# f28p65x_xbar_regs register map
Vendor: Texas Instruments
Peripheral module from a debugger description file (folder C2000).
Address unit: 16 bits
Registers are 32-bit, read-only, no defined reset value unless marked. A register's access mark holds for its fields unless they carry their own. Offsets are as the file gives them; lines under a group give offsets from that group; [hi:lo] are bit positions; {n}, {i} and the like mark numbered series; 'fields as' and 'values as' point back to an identical list; <NAME> marks a mode.

## XBAR_REGS — XBAR Registers
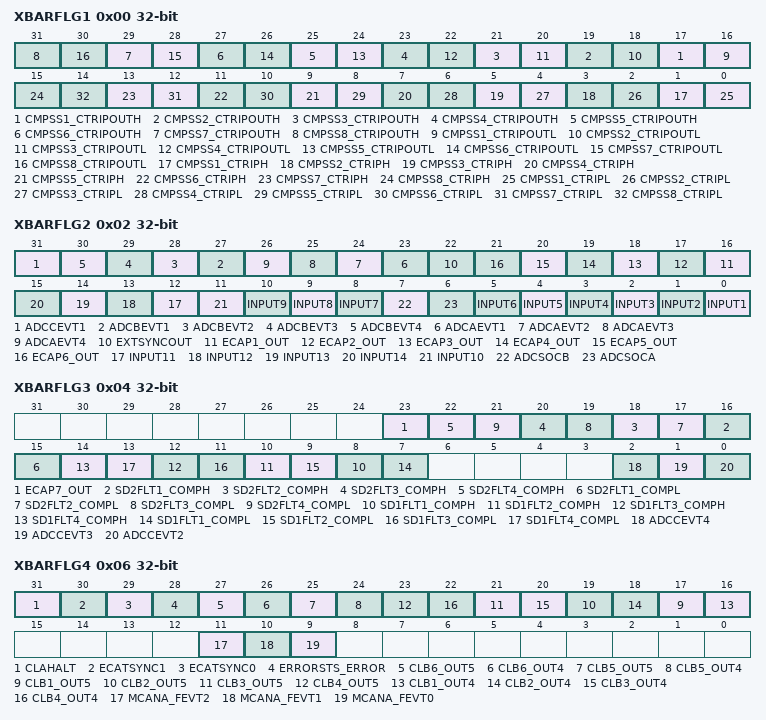
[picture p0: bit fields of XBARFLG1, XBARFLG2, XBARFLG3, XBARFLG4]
0x00 XBARFLG1 — X-Bar Input Flag Register 1
  [2n+15] CMPSS{n}_CTRIPOUTH (n=1..8) — Input Flag for CMPSS{n}.CTRIPOUTH Signal
  [2n+14] CMPSS{n}_CTRIPOUTL (n=1..8) — Input Flag for CMPSS{n}.CTRIPOUTL Signal
  [2n-1] CMPSS{n}_CTRIPH (n=1..8) — Input Flag for CMPSS{n}.CTRIPH Signal
  [2n-2] CMPSS{n}_CTRIPL (n=1..8) — Input Flag for CMPSS{n}.CTRIPL Signal
0x02 XBARFLG2 — X-Bar Input Flag Register 2
  [31] ADCCEVT1 — Input Flag for ADCCEVT1 Signal
  [n+26] ADCBEVT{n} (n=1..4) — Input Flag for ADCBEVT{n} Signal
  [n+22] ADCAEVT{n} (n=1..4) — Input Flag for ADCAEVT{n} Signal
  [22] EXTSYNCOUT — Input Flag for EXTSYNCOUT Signal
  [n+15] ECAP{n}_OUT (n=1..6) — Input Flag for ECAP{n}.OUT Signal
  [n+1] INPUT{n} (n=11..14) — Input Flag for INPUT{n} Signal
  [11] INPUT10 — Input Flag for INPUT10\ Signal
  [10] INPUT9 — Input Flag for INPUT9 Signal
  [9] INPUT8 — Input Flag for INPUT8 Signal
  [8] INPUT7 — Input Flag for INPUT7 Signal
  [7] ADCSOCB — Input Flag for ADCSOCB Signal
  [6] ADCSOCA — Input Flag for ADCSOCA Signal
  [n-1] INPUT{n} (n=1..6) — Input Flag for INPUT{n} Signal
0x04 XBARFLG3 — X-Bar Input Flag Register 3
  [23] ECAP7_OUT — Input Flag for ECAP7.OUT Signal
  [2n+14] SD2FLT{n}_COMPH (n=1..4) — Input Flag for SD2FLT{n}.COMPH Signal
  [2n+13] SD2FLT{n}_COMPL (n=1..4) — Input Flag for SD2FLT{n}.COMPL Signal
  [2n+6] SD1FLT{n}_COMPH (n=1..4) — Input Flag for SD1FLT{n}.COMPH Signal
  [2n+5] SD1FLT{n}_COMPL (n=1..4) — Input Flag for SD1FLT{n}.COMPL Signal
  [2] ADCCEVT4 — Input Flag for ADCCEVT4 Signal
  [1] ADCCEVT3 — Input Flag for ADCCEVT3 Signal
  [0] ADCCEVT2 — Input Flag for ADCCEVT2 Signal
0x06 XBARFLG4 — X-Bar Input Flag Register 4
  [31] CLAHALT — Input Latch for CLAHALT Signal
  [30] ECATSYNC1 — Input Latch for ECATSYNC1 Signal
  [29] ECATSYNC0 — Input Latch for ECATSYNC0 Signal
  [28] ERRORSTS_ERROR — Input Latch for ERRORSTS_ERROR Signal
  [27] CLB6_OUT5 — Input Latch for CLB6_OUT5 Signal
  [26] CLB6_OUT4 — Input Latch for CLB6_OUT4 Signal
  [25] CLB5_OUT5 — Input Latch for CLB5_OUT5 Signal
  [24] CLB5_OUT4 — Input Latch for CLB5_OUT4 Signal
  [2n+15] CLB{n}_OUT5 (n=1..4) — Input Flag for CLB{n}_5.1 Signal
  [2n+14] CLB{n}_OUT4 (n=1..4) — Input Flag for CLB{n}_4.1 Signal
  [11] MCANA_FEVT2 — Input Flag for MCANA_FEVT2 Signal
  [10] MCANA_FEVT1 — Input Flag for MCANA_FEVT1 Signal
  [9] MCANA_FEVT0 — Input Flag for MCANA_FEVT0 Signal
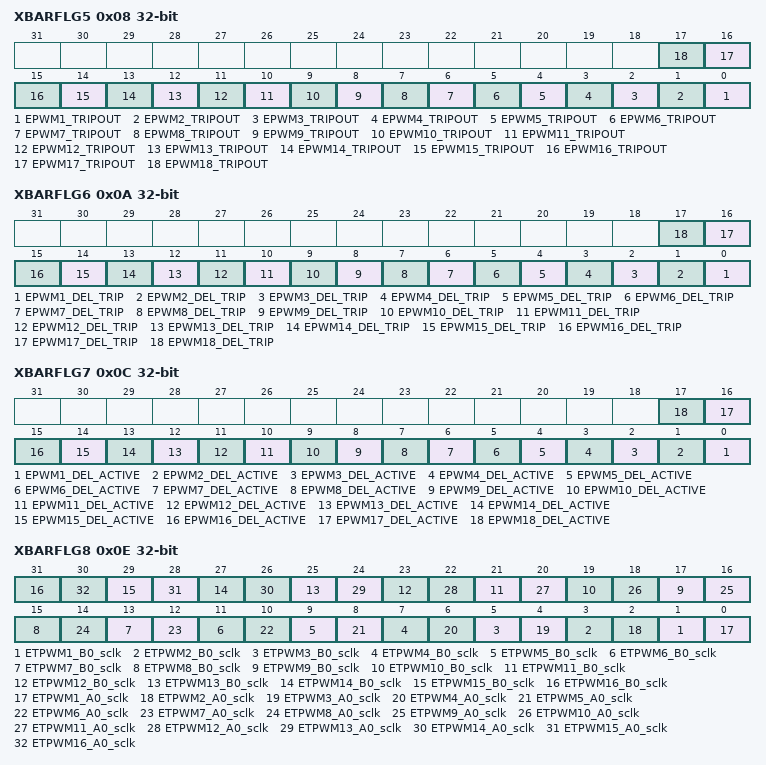
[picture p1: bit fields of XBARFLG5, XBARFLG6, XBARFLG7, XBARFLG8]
0x08 XBARFLG5 — X-Bar Input Flag Register 5
  [n-1] EPWM{n}_TRIPOUT (n=1..18) — Input Flag for EPWM{n}_TRIPOUT Signal
0x0A XBARFLG6 — X-Bar Input Flag Register 6
  [n-1] EPWM{n}_DEL_TRIP (n=1..18) — Input Flag for EPWM{n}_DEL_TRIP Signal
0x0C XBARFLG7 — X-Bar Input Flag Register 7
  [n-1] EPWM{n}_DEL_ACTIVE (n=1..18) — Input Flag for EPWM{n}_DEL_ACTIVE Signal
0x0E XBARFLG8 — X-Bar Input Flag Register 8
  [2n-1] ETPWM{n}_B0_sclk (n=1..16) — Input Flag for ETPWM{n}_B0_sclk Signal
  [2n-2] ETPWM{n}_A0_sclk (n=1..16) — Input Flag for ETPWM{n}_A0_sclk Signal
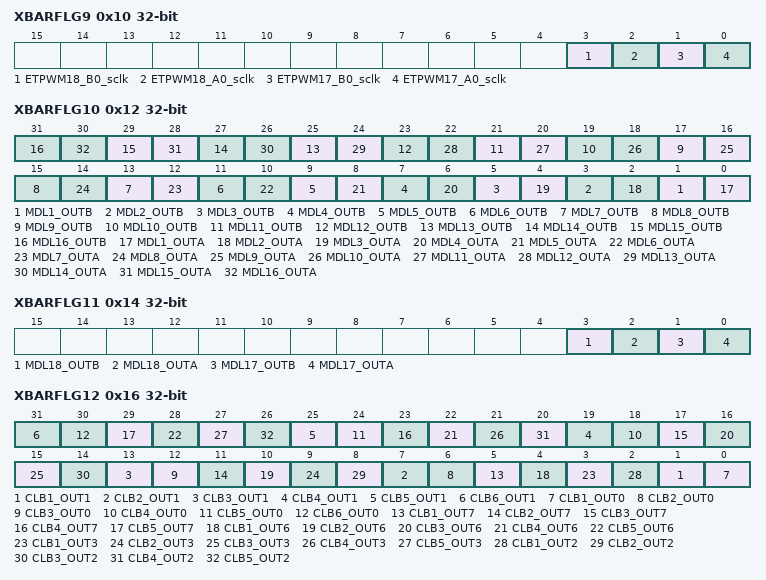
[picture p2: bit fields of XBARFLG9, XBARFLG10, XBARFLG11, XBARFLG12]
0x10 XBARFLG9 — X-Bar Input Flag Register 9
  [3] ETPWM18_B0_sclk — Input Flag for ETPWM18_B0_sclk Signal
  [2] ETPWM18_A0_sclk — Input Flag for ETPWM18_A0_sclk Signal
  [1] ETPWM17_B0_sclk — Input Flag for ETPWM17_B0_sclk Signal
  [0] ETPWM17_A0_sclk — Input Flag for ETPWM17_A0_sclk Signal
0x12 XBARFLG10 — X-Bar Input Flag Register 10
  [2n-1] MDL{n}_OUTB (n=1..16) — Input Flag for MDL{n}_OUTB Signal
  [2n-2] MDL{n}_OUTA (n=1..16) — Input Flag for MDL{n}_OUTA Signal
0x14 XBARFLG11 — X-Bar Input Flag Register 11
  [3] MDL18_OUTB — Input Flag for MDL18_OUTB Signal
  [2] MDL18_OUTA — Input Flag for MDL18_OUTA Signal
  [1] MDL17_OUTB — Input Flag for MDL17_OUTB Signal
  [0] MDL17_OUTA — Input Flag for MDL17_OUTA Signal
0x16 XBARFLG12 — X-Bar Input Flag Register 12
  [6n-5] CLB{n}_OUT1 (n=1..6) — Input Flag for CLB{n}_OUT1 Signal
  [6n-6] CLB{n}_OUT0 (n=1..6) — Input Flag for CLB{n}_OUT0 Signal
  [6n-1] CLB{n}_OUT7 (n=1..5) — Input Flag for CLB{n}_OUT7 Signal
  [6n-2] CLB{n}_OUT6 (n=1..5) — Input Flag for CLB{n}_OUT6 Signal
  [6n-3] CLB{n}_OUT3 (n=1..5) — Input Flag for CLB{n}_OUT3 Signal
  [6n-4] CLB{n}_OUT2 (n=1..5) — Input Flag for CLB{n}_OUT2 Signal
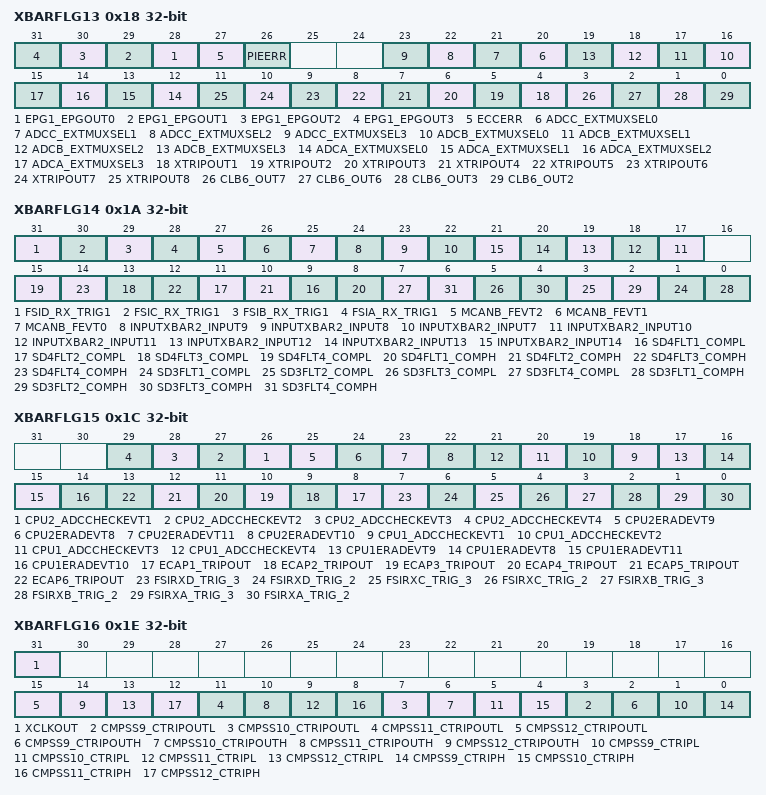
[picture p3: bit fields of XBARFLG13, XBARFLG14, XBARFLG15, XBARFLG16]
0x18 XBARFLG13 — X-Bar Input Flag Register 13
  [n+28] EPG1_EPGOUT{n} (n=0..3) — Input Flag for EPG1_EPGOUT{n} Signal
  [27] ECCERR — Input Flag for ECCERR Signal
  [26] PIEERR — Input Flag for PIEERR Signal
  [n+20] ADCC_EXTMUXSEL{n} (n=0..3) — Input Flag for ADCC_EXTMUXSEL{n} Signal
  [n+16] ADCB_EXTMUXSEL{n} (n=0..3) — Input Flag for ADCB_EXTMUXSEL{n} Signal
  [n+12] ADCA_EXTMUXSEL{n} (n=0..3) — Input Flag for ADCA_EXTMUXSEL{n} Signal
  [n+3] XTRIPOUT{n} (n=1..8) — Input Flag for XTRIPOUT{n} Signal
  [3] CLB6_OUT7 — Input Flag for CLB6_OUT7 Signal
  [2] CLB6_OUT6 — Input Flag for CLB6_OUT6 Signal
  [1] CLB6_OUT3 — Input Flag for CLB6_OUT3 Signal
  [0] CLB6_OUT2 — Input Flag for CLB6_OUT2 Signal
0x1A XBARFLG14 — X-Bar Input Flag Register 14
  [31] FSID_RX_TRIG1 — Input Flag for FSID_RX_TRIG1 Signal
  [30] FSIC_RX_TRIG1 — Input Flag for FSIC_RX_TRIG1 Signal
  [29] FSIB_RX_TRIG1 — Input Flag for FSIB_RX_TRIG1 Signal
  [28] FSIA_RX_TRIG1 — Input Flag for FSIA_RX_TRIG1 Signal
  [27] MCANB_FEVT2 — Input Flag for MCANB_FEVT2 Signal
  [26] MCANB_FEVT1 — Input Flag for MCANB_FEVT1 Signal
  [25] MCANB_FEVT0 — Input Flag for MCANB_FEVT0 Signal
  [24] INPUTXBAR2_INPUT9 — Input Flag for INPUTXBAR2_INPUT9 Signal
  [23] INPUTXBAR2_INPUT8 — Input Flag for INPUTXBAR2_INPUT8 Signal
  [22] INPUTXBAR2_INPUT7 — Input Flag for INPUTXBAR2_INPUT7 Signal
  [n+7] INPUTXBAR2_INPUT{n} (n=10..14) — Input Flag for INPUTXBAR2_INPUT{n} Signal
  [2n+7] SD4FLT{n}_COMPL (n=1..4) — Input Flag for SD4FLT{n}_COMPL Signal
  [2n+6] SD4FLT{n}_COMPH (n=1..4) — Input Flag for SD4FLT{n}_COMPH Signal
  [2n-1] SD3FLT{n}_COMPL (n=1..4) — Input Flag for SD3FLT{n}_COMPL Signal
  [2n-2] SD3FLT{n}_COMPH (n=1..4) — Input Flag for SD3FLT{n}_COMPH Signal
0x1C XBARFLG15 — X-Bar Input Flag Register 15
  [n+25] CPU2_ADCCHECKEVT{n} (n=1..4) — Input Flag for CPU2_ADCCHECKEVT{n} Signal
  [25] CPU2ERADEVT9 — Input Flag for CPU2ERADEVT9 Signal
  [24] CPU2ERADEVT8 — Input Flag for CPU2ERADEVT8 Signal
  [23] CPU2ERADEVT11 — Input Flag for CPU2ERADEVT11 Signal
  [22] CPU2ERADEVT10 — Input Flag for CPU2ERADEVT10 Signal
  [n+17] CPU1_ADCCHECKEVT{n} (n=1..4) — Input Flag for CPU1_ADCCHECKEVT{n} Signal
  [17] CPU1ERADEVT9 — Input Flag for CPU1ERADEVT9 Signal
  [16] CPU1ERADEVT8 — Input Flag for CPU1ERADEVT8 Signal
  [15] CPU1ERADEVT11 — Input Flag for CPU1ERADEVT11 Signal
  [14] CPU1ERADEVT10 — Input Flag for CPU1ERADEVT10 Signal
  [n+7] ECAP{n}_TRIPOUT (n=1..6) — Input Flag for ECAP{n}_TRIPOUT Signal
  [7] FSIRXD_TRIG_3 — Input Flag for FSIRXD_TRIG_3 Signal
  [6] FSIRXD_TRIG_2 — Input Flag for FSIRXD_TRIG_2 Signal
  [5] FSIRXC_TRIG_3 — Input Flag for FSIRXC_TRIG_3 Signal
  [4] FSIRXC_TRIG_2 — Input Flag for FSIRXC_TRIG_2 Signal
  [3] FSIRXB_TRIG_3 — Input Flag for FSIRXB_TRIG_3 Signal
  [2] FSIRXB_TRIG_2 — Input Flag for FSIRXB_TRIG_2 Signal
  [1] FSIRXA_TRIG_3 — Input Flag for FSIRXA_TRIG_3 Signal
  [0] FSIRXA_TRIG_2 — Input Flag for FSIRXA_TRIG_2 Signal
0x1E XBARFLG16 — X-Bar Input Flag Register 16
  [31] XCLKOUT — Input Flag for XCLKOUT Signal
  [4n-33] CMPSS{n}_CTRIPOUTL (n=9..12) — Input Flag for CMPSS{n}_CTRIPOUTL Signal
  [4n-34] CMPSS{n}_CTRIPOUTH (n=9..12) — Input Flag for CMPSS{n}_CTRIPOUTH Signal
  [4n-35] CMPSS{n}_CTRIPL (n=9..12) — Input Flag for CMPSS{n}_CTRIPL Signal
  [4n-36] CMPSS{n}_CTRIPH (n=9..12) — Input Flag for CMPSS{n}_CTRIPH Signal
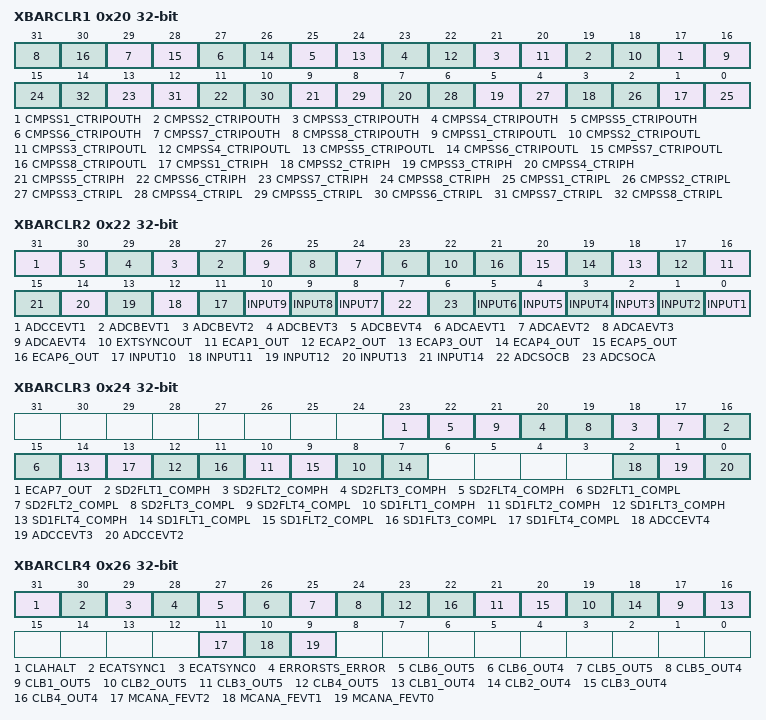
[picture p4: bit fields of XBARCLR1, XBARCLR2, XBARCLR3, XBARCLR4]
0x20 XBARCLR1 rw — X-Bar Input Flag Clear Register 1
  [2n+15] CMPSS{n}_CTRIPOUTH (n=1..8) — Input Flag Clear for CMPSS{n}.CTRIPOUTH Signal
  [2n+14] CMPSS{n}_CTRIPOUTL (n=1..8) — Input Flag Clear for CMPSS{n}.CTRIPOUTL Signal
  [2n-1] CMPSS{n}_CTRIPH (n=1..8) — Input Flag Clear for CMPSS{n}.CTRIPH Signal
  [2n-2] CMPSS{n}_CTRIPL (n=1..8) — Input Flag Clear for CMPSS{n}.CTRIPL Signal
0x22 XBARCLR2 rw — X-Bar Input Flag Clear Register 2
  [31] ADCCEVT1 — Input Flag Clear for ADCCEVT1 Signal
  [n+26] ADCBEVT{n} (n=1..4) — Input Flag Clear for ADCBEVT{n} Signal
  [n+22] ADCAEVT{n} (n=1..4) — Input Flag Clear for ADCAEVT{n} Signal
  [22] EXTSYNCOUT — Input Flag Clear for EXTSYNCOUT Signal
  [n+15] ECAP{n}_OUT (n=1..6) — Input Flag Clear for ECAP{n}.OUT Signal
  [n+1] INPUT{n} (n=7..14) — Input Flag Clear for INPUT{n} Signal
  [7] ADCSOCB — Input Flag Clear for ADCSOCB Signal
  [6] ADCSOCA — Input Flag Clear for ADCSOCA Signal
  [n-1] INPUT{n} (n=1..6) — Input Flag Clear for INPUT{n} Signal
0x24 XBARCLR3 rw — X-Bar Input Flag Clear Register 3
  [23] ECAP7_OUT — Input Flag clear for ECAP7.OUT Signal
  [2n+14] SD2FLT{n}_COMPH (n=1..4) — Input Flag Clear for SD2FLT{n}.COMPH Signal
  [2n+13] SD2FLT{n}_COMPL (n=1..4) — Input Flag Clear for SD2FLT{n}.COMPL Signal
  [2n+6] SD1FLT{n}_COMPH (n=1..4) — Input Flag Clear for SD1FLT{n}.COMPH Signal
  [2n+5] SD1FLT{n}_COMPL (n=1..4) — Input Flag Clear for SD1FLT{n}.COMPL Signal
  [2] ADCCEVT4 — Input Flag Clear for ADCCEVT4 Signal
  [1] ADCCEVT3 — Input Flag Clear for ADCCEVT3 Signal
  [0] ADCCEVT2 — Input Flag Clear for ADCCEVT2 Signal
0x26 XBARCLR4 rw — X-Bar Input Flag Clear Register 4
  [31] CLAHALT — Input Flag clear for CLAHALT Signal
  [30] ECATSYNC1 — Input Latch clear for ECATSYNC1 Signal
  [29] ECATSYNC0 — Input Latch clear for ECATSYNC0 Signal
  [28] ERRORSTS_ERROR — Input Latch clear for ERRORSTS_ERROR Signal
  [27] CLB6_OUT5 — Input Latch clear for CLB6_OUT5 Signal
  [26] CLB6_OUT4 — Input Latch clear for CLB6_OUT4 Signal
  [25] CLB5_OUT5 — Input Latch clear for CLB5_OUT5 Signal
  [24] CLB5_OUT4 — Input Latch clear for CLB5_OUT4 Signal
  [2n+15] CLB{n}_OUT5 (n=1..4) — Input Flag clear for CLB{n}_5.1 Signal
  [2n+14] CLB{n}_OUT4 (n=1..4) — Input Flag clear for CLB{n}_4.1 Signal
  [11] MCANA_FEVT2 — Input Flag clear for MCANA_FEVT2 Signal
  [10] MCANA_FEVT1 — Input Flag clear for MCANA_FEVT1 Signal
  [9] MCANA_FEVT0 — Input Flag clear for MCANA_FEVT0 Signal
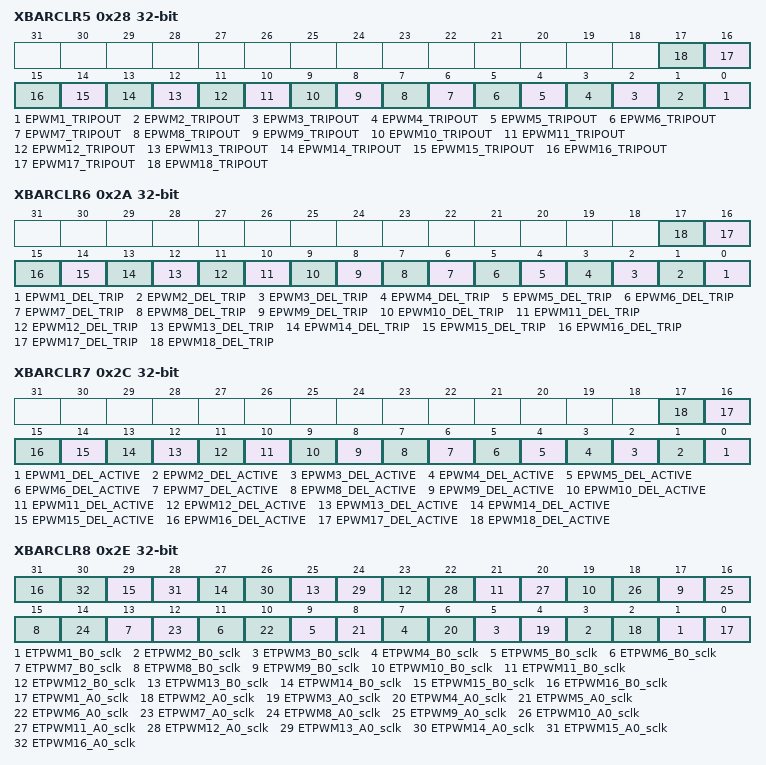
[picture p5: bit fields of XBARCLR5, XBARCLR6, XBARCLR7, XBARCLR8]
0x28 XBARCLR5 rw — X-Bar Input Flag Clear Register 5
  [n-1] EPWM{n}_TRIPOUT (n=1..18) — Input Flag clear for EPWM{n}_TRIPOUT Signal
0x2A XBARCLR6 rw — X-Bar Input Flag Clear Register 6
  [n-1] EPWM{n}_DEL_TRIP (n=1..18) — Input Flag clear for EPWM{n}_DEL_TRIP Signal
0x2C XBARCLR7 rw — X-Bar Input Flag Clear Register 7
  [n-1] EPWM{n}_DEL_ACTIVE (n=1..18) — Input Flag clear for EPWM{n}_DEL_ACTIVE Signal
0x2E XBARCLR8 rw — X-Bar Input Flag Clear Register 8
  [2n-1] ETPWM{n}_B0_sclk (n=1..16) — Input Flag clear for ETPWM{n}_B0_sclk Signal
  [2n-2] ETPWM{n}_A0_sclk (n=1..16) — Input Flag clear for ETPWM{n}_A0_sclk Signal
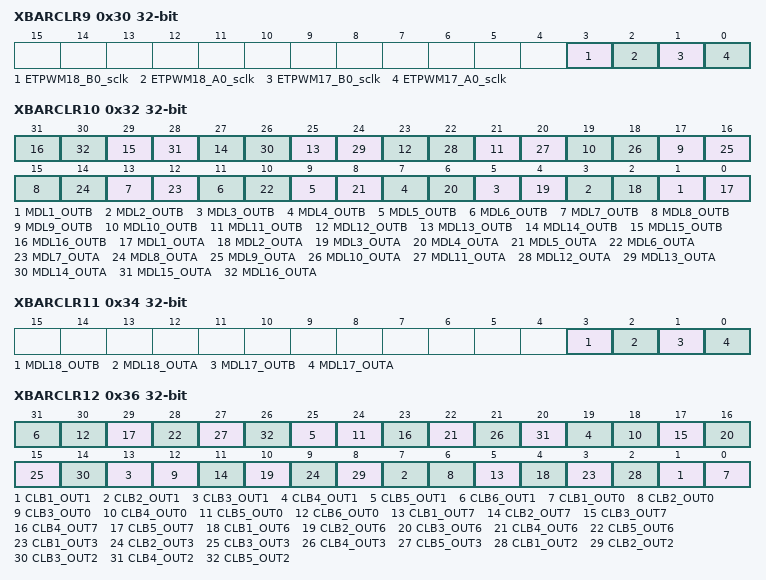
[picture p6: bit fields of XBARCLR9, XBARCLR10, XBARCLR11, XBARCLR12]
0x30 XBARCLR9 rw — X-Bar Input Flag Clear Register 9
  [3] ETPWM18_B0_sclk — Input Flag clear for ETPWM18_B0_sclk Signal
  [2] ETPWM18_A0_sclk — Input Flag clear for ETPWM18_A0_sclk Signal
  [1] ETPWM17_B0_sclk — Input Flag clear for ETPWM17_B0_sclk Signal
  [0] ETPWM17_A0_sclk — Input Flag clear for ETPWM17_A0_sclk Signal
0x32 XBARCLR10 rw — X-Bar Input Flag Clear Register 10
  [2n-1] MDL{n}_OUTB (n=1..16) — Input Flag clear for MDL{n}_OUTB Signal
  [2n-2] MDL{n}_OUTA (n=1..16) — Input Flag clear for MDL{n}_OUTA Signal
0x34 XBARCLR11 rw — X-Bar Input Flag Clear Register 11
  [3] MDL18_OUTB — Input Flag clear for MDL18_OUTB Signal
  [2] MDL18_OUTA — Input Flag clear for MDL18_OUTA Signal
  [1] MDL17_OUTB — Input Flag clear for MDL17_OUTB Signal
  [0] MDL17_OUTA — Input Flag clear for MDL17_OUTA Signal
0x36 XBARCLR12 rw — X-Bar Input Flag Clear Register 12
  [6n-5] CLB{n}_OUT1 (n=1..6) — Input Flag clear for CLB{n}_OUT1 Signal
  [6n-6] CLB{n}_OUT0 (n=1..6) — Input Flag clear for CLB{n}_OUT0 Signal
  [6n-1] CLB{n}_OUT7 (n=1..5) — Input Flag clear for CLB{n}_OUT7 Signal
  [6n-2] CLB{n}_OUT6 (n=1..5) — Input Flag clear for CLB{n}_OUT6 Signal
  [6n-3] CLB{n}_OUT3 (n=1..5) — Input Flag clear for CLB{n}_OUT3 Signal
  [6n-4] CLB{n}_OUT2 (n=1..5) — Input Flag clear for CLB{n}_OUT2 Signal
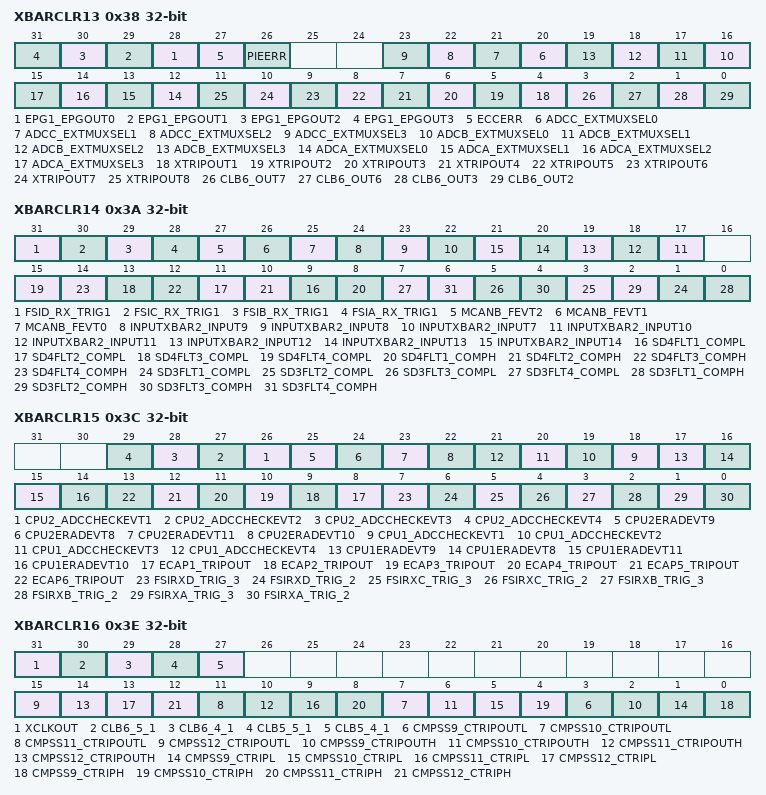
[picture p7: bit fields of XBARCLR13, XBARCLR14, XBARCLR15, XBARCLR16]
0x38 XBARCLR13 rw — X-Bar Input Flag Clear Register 13
  [n+28] EPG1_EPGOUT{n} (n=0..3) — Input Flag clear for EPG1_EPGOUT{n} Signal
  [27] ECCERR — Input Flag clear for ECCERR Signal
  [26] PIEERR — Input Flag clear for PIEERR Signal
  [n+20] ADCC_EXTMUXSEL{n} (n=0..3) — Input Flag clear for ADCC_EXTMUXSEL{n} Signal
  [n+16] ADCB_EXTMUXSEL{n} (n=0..3) — Input Flag clear for ADCB_EXTMUXSEL{n} Signal
  [n+12] ADCA_EXTMUXSEL{n} (n=0..3) — Input Flag clear for ADCA_EXTMUXSEL{n} Signal
  [n+3] XTRIPOUT{n} (n=1..8) — Input Flag clear for XTRIPOUT{n} Signal
  [3] CLB6_OUT7 — Input Flag clear for CLB6_OUT7 Signal
  [2] CLB6_OUT6 — Input Flag clear for CLB6_OUT6 Signal
  [1] CLB6_OUT3 — Input Flag clear for CLB6_OUT3 Signal
  [0] CLB6_OUT2 — Input Flag clear for CLB6_OUT2 Signal
0x3A XBARCLR14 rw — X-Bar Input Flag Clear Register 14
  [31] FSID_RX_TRIG1 — Input Flag clear for FSID_RX_TRIG1 Signal
  [30] FSIC_RX_TRIG1 — Input Flag clear for FSIC_RX_TRIG1 Signal
  [29] FSIB_RX_TRIG1 — Input Flag clear for FSIB_RX_TRIG1 Signal
  [28] FSIA_RX_TRIG1 — Input Flag clear for FSIA_RX_TRIG1 Signal
  [27] MCANB_FEVT2 — Input Flag clear for MCANB_FEVT2 Signal
  [26] MCANB_FEVT1 — Input Flag clear for MCANB_FEVT1 Signal
  [25] MCANB_FEVT0 — Input Flag clear for MCANB_FEVT0 Signal
  [24] INPUTXBAR2_INPUT9 — Input Flag clear for INPUTXBAR2_INPUT9 Signal
  [23] INPUTXBAR2_INPUT8 — Input Flag clear for INPUTXBAR2_INPUT8 Signal
  [22] INPUTXBAR2_INPUT7 — Input Flag clear for INPUTXBAR2_INPUT7 Signal
  [n+7] INPUTXBAR2_INPUT{n} (n=10..14) — Input Flag clear for INPUTXBAR2_INPUT{n} Signal
  [2n+7] SD4FLT{n}_COMPL (n=1..4) — Input Flag clear for SD4FLT{n}_COMPL Signal
  [2n+6] SD4FLT{n}_COMPH (n=1..4) — Input Flag clear for SD4FLT{n}_COMPH Signal
  [2n-1] SD3FLT{n}_COMPL (n=1..4) — Input Flag clear for SD3FLT{n}_COMPL Signal
  [2n-2] SD3FLT{n}_COMPH (n=1..4) — Input Flag clear for SD3FLT{n}_COMPH Signal
0x3C XBARCLR15 rw — X-Bar Input Flag Clear Register 15
  [n+25] CPU2_ADCCHECKEVT{n} (n=1..4) — Input Flag clear for CPU2_ADCCHECKEVT{n} Signal
  [25] CPU2ERADEVT9 — Input Flag clear for CPU2ERADEVT9 Signal
  [24] CPU2ERADEVT8 — Input Flag clear for CPU2ERADEVT8 Signal
  [23] CPU2ERADEVT11 — Input Flag clear for CPU2ERADEVT11 Signal
  [22] CPU2ERADEVT10 — Input Flag clear for CPU2ERADEVT10 Signal
  [n+17] CPU1_ADCCHECKEVT{n} (n=1..4) — Input Flag clear for CPU1_ADCCHECKEVT{n} Signal
  [17] CPU1ERADEVT9 — Input Flag clear for CPU1ERADEVT9 Signal
  [16] CPU1ERADEVT8 — Input Flag clear for CPU1ERADEVT8 Signal
  [15] CPU1ERADEVT11 — Input Flag clear for CPU1ERADEVT11 Signal
  [14] CPU1ERADEVT10 — Input Flag clear for CPU1ERADEVT10 Signal
  [n+7] ECAP{n}_TRIPOUT (n=1..6) — Input Flag clear for ECAP{n}_TRIPOUT Signal
  [7] FSIRXD_TRIG_3 — Input Flag clear for FSIRXD_TRIG_3 Signal
  [6] FSIRXD_TRIG_2 — Input Flag clear for FSIRXD_TRIG_2 Signal
  [5] FSIRXC_TRIG_3 — Input Flag clear for FSIRXC_TRIG_3 Signal
  [4] FSIRXC_TRIG_2 — Input Flag clear for FSIRXC_TRIG_2 Signal
  [3] FSIRXB_TRIG_3 — Input Flag clear for FSIRXB_TRIG_3 Signal
  [2] FSIRXB_TRIG_2 — Input Flag clear for FSIRXB_TRIG_2 Signal
  [1] FSIRXA_TRIG_3 — Input Flag clear for FSIRXA_TRIG_3 Signal
  [0] FSIRXA_TRIG_2 — Input Flag clear for FSIRXA_TRIG_2 Signal
0x3E XBARCLR16 rw — X-Bar Input Flag Clear Register 16
  [31] XCLKOUT — Input Flag clear for XCLKOUT Signal
  [30] CLB6_5_1 — Input Flag clear for CLB6_5_1 Signal
  [29] CLB6_4_1 — Input Flag clear for CLB6_4_1 Signal
  [28] CLB5_5_1 — Input Flag clear for CLB5_5_1 Signal
  [27] CLB5_4_1 — Input Flag clear for CLB5_4_1 Signal
  [4n-33] CMPSS{n}_CTRIPOUTL (n=9..12) — Input Flag clear for CMPSS{n}_CTRIPOUTL Signal
  [4n-34] CMPSS{n}_CTRIPOUTH (n=9..12) — Input Flag clear for CMPSS{n}_CTRIPOUTH Signal
  [4n-35] CMPSS{n}_CTRIPL (n=9..12) — Input Flag clear for CMPSS{n}_CTRIPL Signal
  [4n-36] CMPSS{n}_CTRIPH (n=9..12) — Input Flag clear for CMPSS{n}_CTRIPH Signal
